# STM32F412Zx register map
File version: 1.0
Registers are 32-bit, read-write, reset 0x0 unless marked. A register's access mark holds for its fields unless they carry their own. Offsets are from the block's base; [hi:lo] are bit positions; {n}, {i} and the like mark numbered series.

## USART2 — Universal Synchronous Asynchronous Receiver Transmitter
Base 0x40004400
Same registers: USART3 0x40004800, USART1 0x40011000, USART6 0x40011400
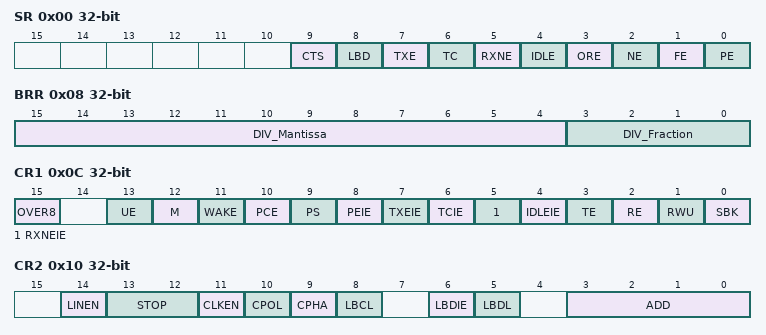
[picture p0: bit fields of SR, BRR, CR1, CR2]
0x00 SR — USART Status register
  [9] CTS — CTS Flag
  [8] LBD — LIN Break Detection Flag
  [7] TXE — Transmit Data Register Empty
  [6] TC — Transmission Complete
  [5] RXNE — Read Data Register Not Empty
  [4] IDLE — IDLE line detected
  [3] ORE — OverRun Error
  [2] NE — Noise Error Flag
  [1] FE — Framing Error
  [0] PE — Parity Error
0x04 DR — USART Data register
  [8:0] DR — Data value
0x08 BRR — USART Baud rate register
  [15:4] DIV_Mantissa — Mantissa of USARTDIV
  [3:0] DIV_Fraction — Fraction of USARTDIV
0x0C CR1 — USART Control register 1
  [15] OVER8 — USART Oversampling by 8 enable
    0=OVERSAMPLING_16 (Oversampling by 16); 1=OVERSAMPLING_8 (Oversampling by 8)
  [13] UE — USART Enable
  [12] M — Word length
    0=DATAWIDTH_8B (8 bits word length : Start bit, 8 data bits, n stop bits); 1=DATAWIDTH_9B (9 bits word length : Start bit, 9 data bits, n stop bits)
  [11] WAKE — Wakeup method
    0=IDLELINE (USART wake up from Mute mode on Idle Line); 1=ADDRESSMARK (USART wake up from Mute mode on Address Mark)
  [10] PCE — Parity Control Enable
  [9] PS — Parity Selection
  [8] PEIE — PE Interrupt Enable
  [7] TXEIE — TXE Interrupt Enable
  [6] TCIE — Transmission Complete Interrupt Enable
  [5] RXNEIE — RXNE Interrupt Enable
  [4] IDLEIE — IDLE Interrupt Enable
  [3] TE — Transmitter Enable
  [2] RE — Receiver Enable
  [1] RWU — Receiver wakeup
  [0] SBK — Send Break
0x10 CR2 — USART Control register 2
  [14] LINEN — LIN mode enable
  [13:12] STOP — STOP[1:0] bits (STOP bits)
    1=STOPBITS_0_5 (0.5 stop bit); 0=STOPBITS_1 (1 stop bit); 3=STOPBITS_1_5 (1.5 stop bits); 2=STOPBITS_2 (2 stop bits)
  [11] CLKEN — Clock Enable
  [10] CPOL — Clock Polarity
    0=LOW (Steady low value on SCLK pin outside transmission window); 1=HIGH (Steady high value on SCLK pin outside transmission window)
  [9] CPHA — Clock Phase
    0=PHASE_1EDGE (The first clock transition is the first data capture edge); 1=PHASE_2EDGE (The second clock transition is the first data capture edge)
  [8] LBCL — Last Bit Clock pulse
    0=NO_OUTPUT (The clock pulse of the last data bit is not output to the SCLK pin); 1=OUTPUT (The clock pulse of the last data bit is output to the SCLK pin)
  [6] LBDIE — LIN Break Detection Interrupt Enable
  [5] LBDL — LIN Break Detection Length
    0=DETECT_10B (10-bit break detection method selected); 1=DETECT_11B (11-bit break detection method selected)
  [3:0] ADD — Address of the USART node
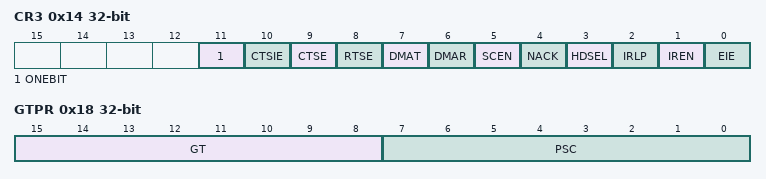
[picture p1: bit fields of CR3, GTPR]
0x14 CR3 — USART Control register 3
  [11] ONEBIT — USART One bit method enable
  [10] CTSIE — CTS Interrupt Enable
  [9] CTSE — CTS Enable
  [8] RTSE — RTS Enable
  [7] DMAT — DMA Enable Transmitter
  [6] DMAR — DMA Enable Receiver
  [5] SCEN — Smartcard mode enable
  [4] NACK — Smartcard NACK enable
  [3] HDSEL — Half-Duplex Selection
  [2] IRLP — IrDA Low-Power
    0=NORMAL (IrDA normal power mode); 1=LOW (IrDA low power mode)
  [1] IREN — IrDA mode Enable
  [0] EIE — Error Interrupt Enable
0x18 GTPR — USART Guard time and prescaler register
  [15:8] GT — Guard time value
  [7:0] PSC — PSC[7:0] bits (Prescaler value)

## I2C1 — Inter-integrated Circuit Interface
Base 0x40005400
Same registers: I2C2 0x40005800, I2C3 0x40005C00
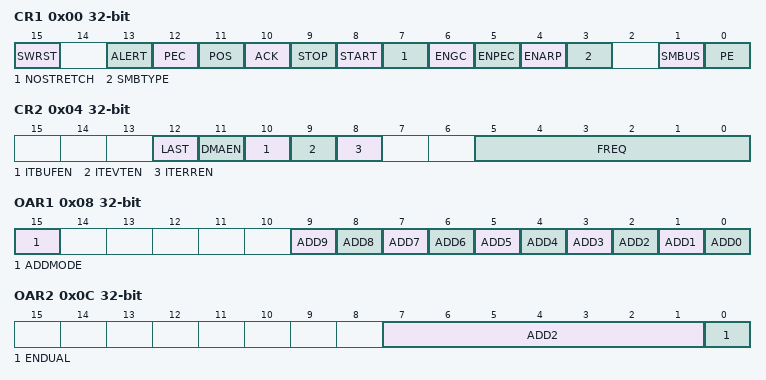
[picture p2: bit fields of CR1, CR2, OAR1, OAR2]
0x00 CR1 — I2C Control register 1
  [15] SWRST — Software Reset
  [13] ALERT — SMBus Alert
  [12] PEC — Packet Error Checking
  [11] POS — Acknowledge/PEC Position (for data reception)
  [10] ACK — Acknowledge Enable
    1=ACK (ACK is sent after current received byte.); 0=NACK (NACK is sent after current received byte.)
  [9] STOP — Stop Generation
  [8] START — Start Generation
  [7] NOSTRETCH — Clock Stretching Disable (Slave mode)
  [6] ENGC — General Call Enable
  [5] ENPEC — PEC Enable
  [4] ENARP — ARP Enable
  [3] SMBTYPE — SMBus Type
  [1] SMBUS — SMBus Mode
  [0] PE — Peripheral Enable
0x04 CR2 — I2C Control register 2
  [12] LAST — DMA Last Transfer
  [11] DMAEN — DMA Requests Enable
  [10] ITBUFEN — Buffer Interrupt Enable
  [9] ITEVTEN — Event Interrupt Enable
  [8] ITERREN — Error Interrupt Enable
  [5:0] FREQ — FREQ[5:0] bits (Peripheral Clock Frequency)
0x08 OAR1 — I2C Own address register 1
  [15] ADDMODE — Addressing Mode (Slave mode)
  [n] ADD{n} (n=0..9) — Bit {n}
0x0C OAR2 — I2C Own address register 2
  [7:1] ADD2 — Interface address
  [0] ENDUAL — Dual addressing mode enable
0x10 DR — I2C Data register
  [7:0] DR — 8-bit Data Register
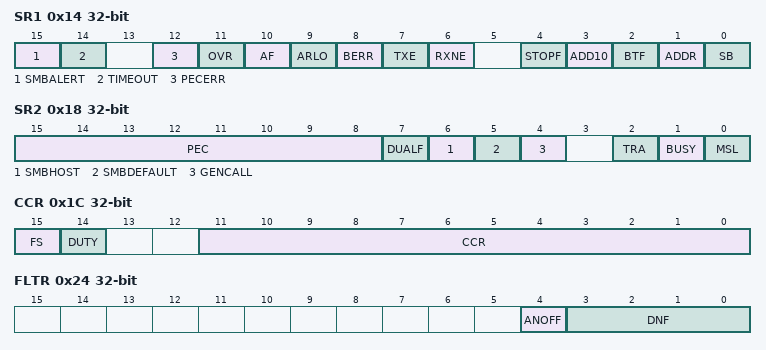
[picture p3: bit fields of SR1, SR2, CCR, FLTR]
0x14 SR1 — I2C Status register 1
  [15] SMBALERT — SMBus Alert
  [14] TIMEOUT — Timeout or Tlow Error
  [12] PECERR — PEC Error in reception
  [11] OVR — Overrun/Underrun
  [10] AF — Acknowledge Failure
  [9] ARLO — Arbitration Lost (master mode)
  [8] BERR — Bus Error
  [7] TXE — Data Register Empty (transmitters)
  [6] RXNE — Data Register not Empty (receivers)
  [4] STOPF — Stop detection (Slave mode)
  [3] ADD10 — 10-bit header sent (Master mode)
  [2] BTF — Byte Transfer Finished
  [1] ADDR — Address sent (master mode)/matched (slave mode)
  [0] SB — Start Bit (Master mode)
0x18 SR2 — I2C Status register 2
  [15:8] PEC — Packet Error Checking Register
  [7] DUALF — Dual Flag (Slave mode)
  [6] SMBHOST — SMBus Host Header (Slave mode)
  [5] SMBDEFAULT — SMBus Device Default Address (Slave mode)
  [4] GENCALL — General Call Address (Slave mode)
  [2] TRA — Transmitter/Receiver
    1=WRITE (Bus is in write transfer); 0=READ (Bus is in read transfer)
  [1] BUSY — Bus Busy
  [0] MSL — Master/Slave
0x1C CCR — I2C Clock control register
  [15] FS — I2C Master Mode Selection
    0=STANDARD_MODE (Master clock speed range is standard mode); 1=FAST_MODE (Master clock speed range is fast mode)
  [14] DUTY — Fast Mode Duty Cycle
    0=DUTYCYCLE_2 (I2C fast mode Tlow/Thigh = 2); 1=DUTYCYCLE_16_9 (I2C fast mode Tlow/Thigh = 16/9)
  [11:0] CCR — Clock Control Register in Fast/Standard mode (Master mode)
0x20 TRISE — I2C TRISE register
  [5:0] TRISE — Maximum Rise Time in Fast/Standard mode (Master mode)
0x24 FLTR — I2C FLTR register
  [4] ANOFF — Analog Noise Filter OFF
  [3:0] DNF — Digital Noise Filter
